# ESP32S31_RADIO register map
Vendor: Espressif; Series: ESP32-S31; File version: 3.52
Registers are 32-bit, read-write, no defined reset value unless marked. A register's access mark holds for its fields unless they carry their own. Offsets are from the block's base; [hi:lo] are bit positions; {n}, {i} and the like mark numbered series; 'fields as' and 'values as' point back to an identical list.

## I2C_ANA_MST — Shared ESP32-S31 analog-register I2C master owned by the affine radio-PHY lifecycle.
Base 0x2010F800
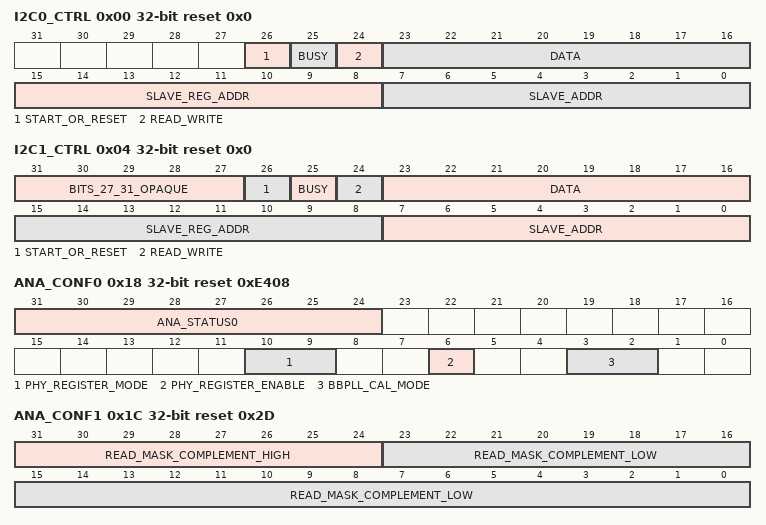
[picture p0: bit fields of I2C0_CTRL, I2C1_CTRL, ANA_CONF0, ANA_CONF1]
0x00 I2C0_CTRL reset 0x0 — Analog-register I2C host-0 command and completion word.
  [26] START_OR_RESET wo — SOURCE: ROM_REV0_PHY_I2C stores this bit alone to reset the host; a start role and a read value are not established.
  [25] BUSY ro
  [24] READ_WRITE
  [23:16] DATA
  [15:8] SLAVE_REG_ADDR
  [7:0] SLAVE_ADDR
0x04 I2C1_CTRL reset 0x0 — Analog-register I2C host-1 command and completion word.
  [31:27] BITS_27_31_OPAQUE — Opaque: meaning not established. Observed source use; the individual hardware meaning is unknown.
  [26] START_OR_RESET wo — SOURCE: ROM_REV0_PHY_I2C stores this bit alone to reset the host; a start role and a read value are not established.
  [25] BUSY ro
  [24] READ_WRITE
  [23:16] DATA
  [15:8] SLAVE_REG_ADDR
  [7:0] SLAVE_ADDR
0x18 ANA_CONF0 reset 0xE408 — Shared analog-I2C master control used by PHY register mode and BBPLL calibration.
  [31:24] ANA_STATUS0 ro
  [10:9] PHY_REGISTER_MODE
    2=REGISTER_MODE
  [6] PHY_REGISTER_ENABLE
  [3:2] BBPLL_CAL_MODE — Project-assigned name. Reviewed two-bit BBPLL calibration mode; complete ROM uses encodings one and two.
    1=DISABLED; 2=ENABLED
0x1C ANA_CONF1 reset 0x2D — Shared analog-I2C routing and read-mask word.
  [31:24] READ_MASK_COMPLEMENT_HIGH ro — Project-assigned name. High byte of the complete complemented PHY-I2C read-mask publication.
  [23:0] READ_MASK_COMPLEMENT_LOW — Project-assigned name. Low 24 bits of the complete complemented PHY-I2C read-mask publication.
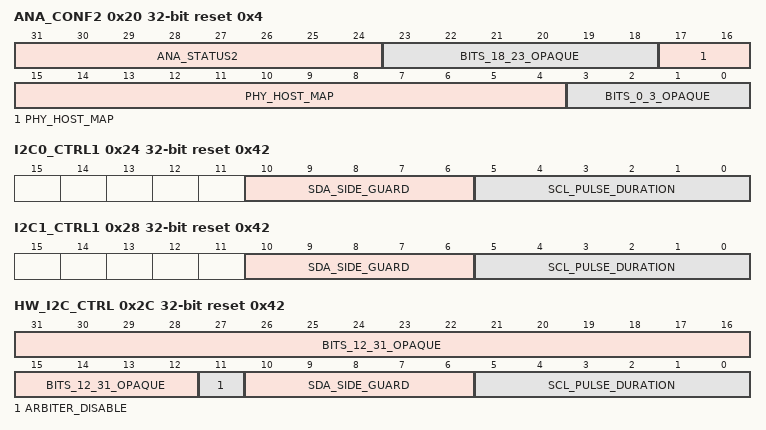
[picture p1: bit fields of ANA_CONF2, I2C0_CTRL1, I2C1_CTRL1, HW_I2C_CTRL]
0x20 ANA_CONF2 reset 0x4 — Shared analog-I2C host-selection word.
  [31:24] ANA_STATUS2 ro
  [23:18] BITS_18_23_OPAQUE — Opaque: meaning not established. Observed source use; the individual hardware meaning is unknown.
  [17:4] PHY_HOST_MAP — Project-assigned name. Complete host-selection field replaced by phy_get_i2c_hostid_new while unrelated bits are preserved.
    0x3FA0=REVIEWED_RADIO_MAP
  [3:0] BITS_0_3_OPAQUE — Opaque: meaning not established. Observed source use; the individual hardware meaning is unknown.
0x24 I2C0_CTRL1 reset 0x42 — Host-0 timing and clock-selection control.
  [10:6] SDA_SIDE_GUARD — Project-assigned name.
  [5:0] SCL_PULSE_DURATION — Project-assigned name.
0x28 I2C1_CTRL1 reset 0x42 — Host-1 timing and clock-selection control.
  fields as I2C0_CTRL1
0x2C HW_I2C_CTRL reset 0x42 — Hardware-host timing and clock-selection control.
  [31:12] BITS_12_31_OPAQUE — Opaque: meaning not established. Observed source use; the individual hardware meaning is unknown.
  [11] ARBITER_DISABLE — Project-assigned name.
  [10:6] SDA_SIDE_GUARD — Project-assigned name.
  [5:0] SCL_PULSE_DURATION — Project-assigned name.

## PHY_I2C_COMMAND_RAM — Official S31 reg_base.h names this aperture DR_REG_I2C_ANA_MST_MEM_BASE. The complete blob establishes its forty-five-entry command layout and the population order in phy_i2c_master_cmd_mem_init. Complete phy_i2c_check independently names ten logical banks, their block IDs, selected host and finite register-index ranges.
Base 0x2010FC00
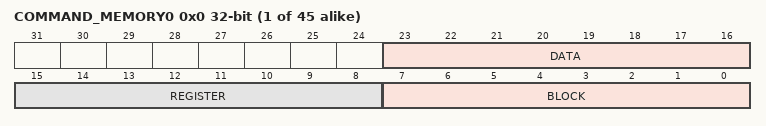
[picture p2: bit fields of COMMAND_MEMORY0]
{0x0+4i} COMMAND_MEMORY{i} (i=0..44) wo — Project-assigned name. One PHY-I2C master command-memory entry; the public header proves the containing memory aperture while the complete blob proves this word layout.
  [23:16] DATA — Project-assigned name.
  [15:8] REGISTER — Project-assigned name.
  [7:0] BLOCK — Project-assigned name. Logical PHY-I2C block ID. The bank host and valid half-open register-index ranges are: SAR1 host 0 [0,7), ULP host 1 [0,11), RFPLL host 1 [0,22), RFPLL_SDM host 1 [0,7), BBPLL host 0 [0,11), BBTOP host 1 [0,57), PERIF host 0 [0,13), BIAS host 1 [0,4), TXRF host 1 [1,22), DIG_REG host 0 [0,15).
    16=SAR1; 97=ULP; 98=RFPLL; 99=RFPLL_SDM; 102=BBPLL; 103=BBTOP; 105=PERIF; 106=BIAS; 107=TXRF; 109=DIG_REG
